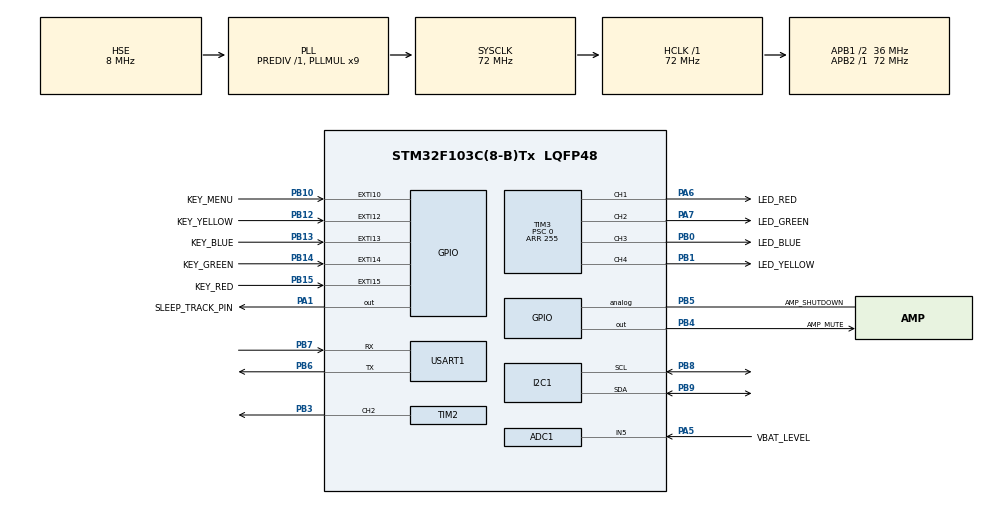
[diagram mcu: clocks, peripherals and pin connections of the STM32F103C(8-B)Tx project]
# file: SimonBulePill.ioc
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ADC1.Channel-8\#ChannelRegularConversion=ADC_CHANNEL_5
ADC1.NbrOfConversion=1
ADC1.NbrOfConversionFlag=1
ADC1.Rank-8\#ChannelRegularConversion=1
ADC1.SamplingTime-8\#ChannelRegularConversion=ADC_SAMPLETIME_239CYCLES_5
ADC1.master=1
Dma.Request0=TIM4_UP
Dma.TIM4_UP.0.Direction=DMA_MEMORY_TO_PERIPH
Dma.TIM4_UP.0.Instance=DMA1_Channel7
Dma.TIM4_UP.0.MemDataAlignment=DMA_MDATAALIGN_HALFWORD
Dma.TIM4_UP.0.MemInc=DMA_MINC_ENABLE
Dma.TIM4_UP.0.Mode=DMA_CIRCULAR
Dma.TIM4_UP.0.PeriphDataAlignment=DMA_PDATAALIGN_WORD
Dma.TIM4_UP.0.PeriphInc=DMA_PINC_DISABLE
Dma.TIM4_UP.0.Priority=DMA_PRIORITY_HIGH
Mcu.Family=STM32F1
Mcu.Name=STM32F103C(8-B)Tx
Mcu.Package=LQFP48
NVIC.DMA1_Channel7_IRQn=true\:0\:0\:false\:false\:true\:false\:true\:true
NVIC.EXTI15_10_IRQn=true\:0\:0\:false\:false\:true\:true\:true\:true
NVIC.PriorityGroup=NVIC_PRIORITYGROUP_4
NVIC.RTC_Alarm_IRQn=true\:0\:0\:false\:false\:true\:true\:true\:true
NVIC.RTC_IRQn=true\:0\:0\:false\:false\:true\:true\:true\:true
NVIC.TIM1_CC_IRQn=true\:0\:0\:false\:false\:true\:true\:true\:true
NVIC.TIM1_UP_IRQn=true\:0\:0\:false\:false\:true\:true\:true\:true
PA0-WKUP.Mode=SYS_WakeUp0
PA0-WKUP.Signal=SYS_WKUP
PA1.GPIO_Label=SLEEP_TRACK_PIN
PA1.GPIO_ModeDefaultOutputPP=GPIO_MODE_OUTPUT_PP
PA1.Signal=GPIO_Output
PA13.Mode=Serial_Wire
PA13.Signal=SYS_JTMS-SWDIO
PA14.Mode=Serial_Wire
PA14.Signal=SYS_JTCK-SWCLK
PA5.GPIO_Label=VBAT_LEVEL
PA5.Signal=ADCx_IN5
PA6.GPIO_Label=LED_RED
PA6.GPIO_ModeDefaultPP=GPIO_MODE_AF_PP
PA6.Signal=S_TIM3_CH1
PA7.GPIO_Label=LED_GREEN
PA7.GPIO_ModeDefaultPP=GPIO_MODE_AF_PP
PA7.Signal=S_TIM3_CH2
PB0.GPIO_Label=LED_BLUE
PB0.GPIO_ModeDefaultPP=GPIO_MODE_AF_PP
PB0.Signal=S_TIM3_CH3
PB1.GPIO_Label=LED_YELLOW
PB1.GPIO_ModeDefaultPP=GPIO_MODE_AF_PP
PB1.Signal=S_TIM3_CH4
PB10.GPIO_Label=KEY_MENU
PB10.GPIO_ModeDefaultEXTI=GPIO_MODE_IT_RISING_FALLING
PB10.GPIO_PuPd=GPIO_PULLDOWN
PB10.Signal=GPXTI10
PB12.GPIO_Label=KEY_YELLOW
PB12.GPIO_ModeDefaultEXTI=GPIO_MODE_IT_RISING_FALLING
PB12.GPIO_PuPd=GPIO_PULLDOWN
PB12.Signal=GPXTI12
PB13.GPIO_Label=KEY_BLUE
PB13.GPIO_ModeDefaultEXTI=GPIO_MODE_IT_RISING_FALLING
PB13.GPIO_PuPd=GPIO_PULLDOWN
PB13.Signal=GPXTI13
PB14.GPIO_Label=KEY_GREEN
PB14.GPIO_ModeDefaultEXTI=GPIO_MODE_IT_RISING_FALLING
PB14.GPIO_PuPd=GPIO_PULLDOWN
PB14.Signal=GPXTI14
PB15.GPIO_Label=KEY_RED
PB15.GPIO_ModeDefaultEXTI=GPIO_MODE_IT_RISING_FALLING
PB15.GPIO_PuPd=GPIO_PULLDOWN
PB15.Signal=GPXTI15
PB3.Signal=S_TIM2_CH2
PB4.GPIO_Label=AMP_MUTE
PB4.PinState=GPIO_PIN_RESET
PB4.Signal=GPIO_Output
PB5.GPIO_Label=AMP_SHUTDOWN
PB5.Signal=GPIO_Analog
PB6.Mode=Asynchronous
PB6.Signal=USART1_TX
PB7.Mode=Asynchronous
PB7.Signal=USART1_RX
PB8.Mode=I2C
PB8.Signal=I2C1_SCL
PB9.Mode=I2C
PB9.Signal=I2C1_SDA
PD0-OSC_IN.Mode=HSE-External-Oscillator
PD0-OSC_IN.Signal=RCC_OSC_IN
PD1-OSC_OUT.Mode=HSE-External-Oscillator
PD1-OSC_OUT.Signal=RCC_OSC_OUT
ProjectManager.HeapSize=0x200
ProjectManager.StackSize=0x400
ProjectManager.TargetToolchain=STM32CubeIDE
RCC.ADCPresc=RCC_ADCPCLK2_DIV6
RCC.AHBFreq_Value=72000000
RCC.APB1CLKDivider=RCC_HCLK_DIV2
RCC.APB1Freq_Value=36000000
RCC.APB1TimFreq_Value=72000000
RCC.APB2Freq_Value=72000000
RCC.APB2TimFreq_Value=72000000
RCC.HCLKFreq_Value=72000000
RCC.PLLMUL=RCC_PLL_MUL9
RCC.PLLSourceVirtual=RCC_PLLSOURCE_HSE
RCC.SYSCLKFreq_VALUE=72000000
RCC.SYSCLKSource=RCC_SYSCLKSOURCE_PLLCLK
RCC.USBFreq_Value=72000000
RTC.AsynchPrediv=40 - 1
RTC.AutoPrediv=0
SH.ADCx_IN5.0=ADC1_IN5,IN5
SH.S_TIM2_CH2.0=TIM2_CH2,PWM Generation2 CH2
SH.S_TIM3_CH1.0=TIM3_CH1,PWM Generation1 CH1
SH.S_TIM3_CH2.0=TIM3_CH2,PWM Generation2 CH2
SH.S_TIM3_CH3.0=TIM3_CH3,PWM Generation3 CH3
SH.S_TIM3_CH4.0=TIM3_CH4,PWM Generation4 CH4
TIM1.AutoReloadPreload=TIM_AUTORELOAD_PRELOAD_DISABLE
TIM1.Channel-Output\ Compare1\ No\ Output=TIM_CHANNEL_1
TIM1.ClockDivision=TIM_CLOCKDIVISION_DIV1
TIM1.OC1Preload=DISABLE
TIM1.Period=400
TIM1.Prescaler=36000
TIM1.RepetitionCounter=1
TIM2.AutoReloadPreload=TIM_AUTORELOAD_PRELOAD_ENABLE
TIM2.Channel-PWM\ Generation2\ CH2=TIM_CHANNEL_2
TIM2.OC2Preload_PWM=ENABLE
TIM2.OCFastMode_PWM-PWM\ Generation2\ CH2=TIM_OCFAST_DISABLE
TIM2.Period=1024 - 1
TIM3.AutoReloadPreload=TIM_AUTORELOAD_PRELOAD_ENABLE
TIM3.Channel-PWM\ Generation1\ CH1=TIM_CHANNEL_1
TIM3.Channel-PWM\ Generation2\ CH2=TIM_CHANNEL_2
TIM3.Channel-PWM\ Generation3\ CH3=TIM_CHANNEL_3
TIM3.Channel-PWM\ Generation4\ CH4=TIM_CHANNEL_4
TIM3.CounterMode=TIM_COUNTERMODE_UP
TIM3.OCMode_PWM-PWM\ Generation1\ CH1=TIM_OCMODE_PWM1
TIM3.OCMode_PWM-PWM\ Generation2\ CH2=TIM_OCMODE_PWM1
TIM3.OCMode_PWM-PWM\ Generation3\ CH3=TIM_OCMODE_PWM1
TIM3.OCMode_PWM-PWM\ Generation4\ CH4=TIM_OCMODE_PWM1
TIM3.OCPolarity_1=TIM_OCPOLARITY_LOW
TIM3.OCPolarity_2=TIM_OCPOLARITY_LOW
TIM3.OCPolarity_3=TIM_OCPOLARITY_LOW
TIM3.OCPolarity_4=TIM_OCPOLARITY_LOW
TIM3.Period=255
TIM3.Prescaler=0
TIM3.Pulse-PWM\ Generation1\ CH1=0
TIM3.Pulse-PWM\ Generation2\ CH2=0
TIM3.Pulse-PWM\ Generation3\ CH3=0
TIM3.Pulse-PWM\ Generation4\ CH4=0
TIM4.AutoReloadPreload=TIM_AUTORELOAD_PRELOAD_ENABLE
TIM4.Period=100
USART1.VirtualMode=VM_ASYNC
VP_CRC_VS_CRC.Mode=CRC_Activate
VP_RTC_VS_RTC_Activate.Mode=RTC_Enabled
VP_TIM1_VS_ClockSourceINT.Mode=Internal
VP_TIM1_VS_no_output1.Mode=Output Compare1 No Output
VP_TIM2_VS_ClockSourceINT.Mode=Internal
VP_TIM3_VS_ClockSourceINT.Mode=Internal
VP_TIM4_VS_ClockSourceINT.Mode=Internal
board=custom

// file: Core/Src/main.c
/* USER CODE BEGIN Header */
/**
  ******************************************************************************
  * @file           : main.c
  * @brief          : Main program body
  ******************************************************************************
  * @attention
  *
  * Copyright (c) 2024 STMicroelectronics.
  * All rights reserved.
  *
  * This software is licensed under terms that can be found in the LICENSE file
  * in the root directory of this software component.
  * If no LICENSE file comes with this software, it is provided AS-IS.
  *
  ******************************************************************************
  */
/* USER CODE END Header */
#include "main.h"
#include "adc.h"
#include "crc.h"
#include "dma.h"
#include "i2c.h"
#include "rtc.h"
#include "tim.h"
#include "usart.h"
#include "gpio.h"

/* USER CODE BEGIN Includes */
#include "game.h"
#include "sleepManager.h"
/* USER CODE END Includes */

void SystemClock_Config(void);

int main(void)
{

  /* MCU Configuration--------------------------------------------------------*/

  /* Reset of all peripherals, Initializes the Flash interface and the Systick. */
  HAL_Init();

  /* Configure the system clock */
  SystemClock_Config();

  /* Initialize all configured peripherals */
  MX_GPIO_Init();
  MX_DMA_Init();
  MX_ADC1_Init();
  MX_I2C1_Init();
  MX_TIM3_Init();
  MX_TIM1_Init();
  MX_TIM2_Init();
  MX_USART1_UART_Init();
  MX_TIM4_Init();
  MX_CRC_Init();
  MX_RTC_Init();
  /* USER CODE BEGIN 2 */
  sleepManagerInit();
  gameInit();
  /* USER CODE END 2 */

  /* Infinite loop */
  /* USER CODE BEGIN WHILE */
  while (gameIsRunning())
  {
      gameProcess();
      // Enter low-power mode, waiting for the next interrupt
      sleepManagerProcess();
    /* USER CODE END WHILE */

    /* USER CODE BEGIN 3 */
  }
  sleepManagerEnterStandbyMode();
  /* USER CODE END 3 */
}

void SystemClock_Config(void)
{
  RCC_OscInitTypeDef RCC_OscInitStruct = {0};
  RCC_ClkInitTypeDef RCC_ClkInitStruct = {0};
  RCC_PeriphCLKInitTypeDef PeriphClkInit = {0};

  /** Initializes the RCC Oscillators according to the specified parameters
  * in the RCC_OscInitTypeDef structure.
  */
  RCC_OscInitStruct.OscillatorType = RCC_OSCILLATORTYPE_LSI|RCC_OSCILLATORTYPE_HSE;
  RCC_OscInitStruct.HSEState = RCC_HSE_ON;
  RCC_OscInitStruct.HSEPredivValue = RCC_HSE_PREDIV_DIV1;
  RCC_OscInitStruct.HSIState = RCC_HSI_ON;
  RCC_OscInitStruct.LSIState = RCC_LSI_ON;
  RCC_OscInitStruct.PLL.PLLState = RCC_PLL_ON;
  RCC_OscInitStruct.PLL.PLLSource = RCC_PLLSOURCE_HSE;
  RCC_OscInitStruct.PLL.PLLMUL = RCC_PLL_MUL9;
  if (HAL_RCC_OscConfig(&RCC_OscInitStruct) != HAL_OK)
  {
    Error_Handler();
  }

  /** Initializes the CPU, AHB and APB buses clocks
  */
  RCC_ClkInitStruct.ClockType = RCC_CLOCKTYPE_HCLK|RCC_CLOCKTYPE_SYSCLK
                              |RCC_CLOCKTYPE_PCLK1|RCC_CLOCKTYPE_PCLK2;
  RCC_ClkInitStruct.SYSCLKSource = RCC_SYSCLKSOURCE_PLLCLK;
  RCC_ClkInitStruct.AHBCLKDivider = RCC_SYSCLK_DIV1;
  RCC_ClkInitStruct.APB1CLKDivider = RCC_HCLK_DIV2;
  RCC_ClkInitStruct.APB2CLKDivider = RCC_HCLK_DIV1;

  if (HAL_RCC_ClockConfig(&RCC_ClkInitStruct, FLASH_LATENCY_2) != HAL_OK)
  {
    Error_Handler();
  }
  PeriphClkInit.PeriphClockSelection = RCC_PERIPHCLK_RTC|RCC_PERIPHCLK_ADC;
  PeriphClkInit.RTCClockSelection = RCC_RTCCLKSOURCE_LSI;
  PeriphClkInit.AdcClockSelection = RCC_ADCPCLK2_DIV6;
  if (HAL_RCCEx_PeriphCLKConfig(&PeriphClkInit) != HAL_OK)
  {
    Error_Handler();
  }
}

void Error_Handler(void)
{
  __disable_irq();
  while (1)
  {
  }
}
